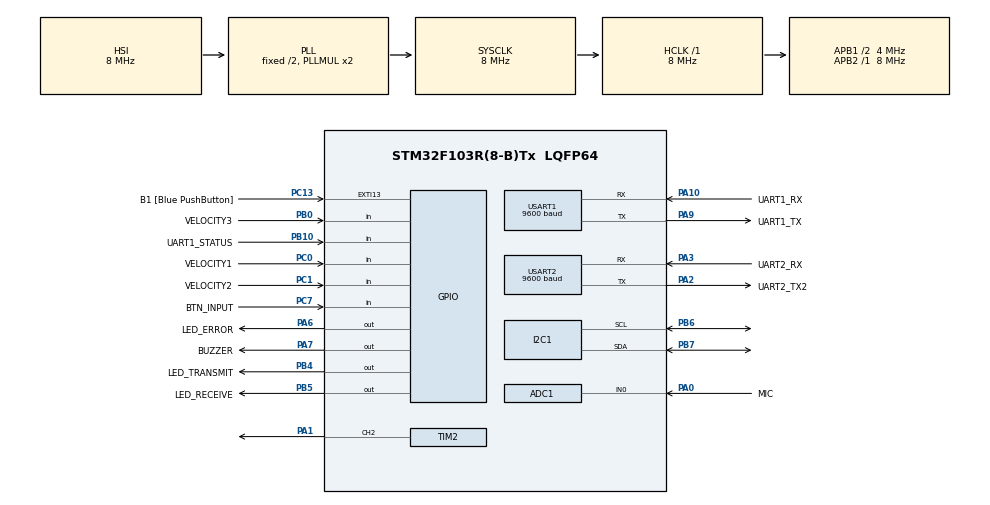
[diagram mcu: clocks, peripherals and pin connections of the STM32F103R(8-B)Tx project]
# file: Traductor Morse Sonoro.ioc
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ADC1.Channel-0\#ChannelRegularConversion=ADC_CHANNEL_0
ADC1.ContinuousConvMode=DISABLE
ADC1.ExternalTrigConv=ADC_EXTERNALTRIGCONV_T2_CC2
ADC1.NbrOfConversionFlag=1
ADC1.Rank-0\#ChannelRegularConversion=1
ADC1.SamplingTime-0\#ChannelRegularConversion=ADC_SAMPLETIME_1CYCLE_5
ADC1.master=1
Dma.ADC1.0.Direction=DMA_PERIPH_TO_MEMORY
Dma.ADC1.0.Instance=DMA1_Channel1
Dma.ADC1.0.MemDataAlignment=DMA_MDATAALIGN_HALFWORD
Dma.ADC1.0.MemInc=DMA_MINC_ENABLE
Dma.ADC1.0.Mode=DMA_NORMAL
Dma.ADC1.0.PeriphDataAlignment=DMA_PDATAALIGN_HALFWORD
Dma.ADC1.0.PeriphInc=DMA_PINC_DISABLE
Dma.ADC1.0.Priority=DMA_PRIORITY_MEDIUM
Dma.Request0=ADC1
Mcu.Family=STM32F1
Mcu.Name=STM32F103R(8-B)Tx
Mcu.Package=LQFP64
NVIC.DMA1_Channel1_IRQn=true\:0\:0\:false\:false\:true\:false\:true\:true
NVIC.EXTI15_10_IRQn=true\:0\:0\:false\:false\:true\:true\:true\:true
NVIC.PriorityGroup=NVIC_PRIORITYGROUP_4
NVIC.USART1_IRQn=true\:0\:0\:false\:false\:true\:true\:true\:true
PA0-WKUP.GPIO_Label=MIC
PA0-WKUP.Signal=ADCx_IN0
PA1.Signal=S_TIM2_CH2
PA10.GPIO_Label=UART1_RX
PA10.Mode=Asynchronous
PA10.Signal=USART1_RX
PA13.GPIO_Label=TMS
PA13.Mode=Serial_Wire
PA13.Signal=SYS_JTMS-SWDIO
PA14.GPIO_Label=TCK
PA14.Mode=Serial_Wire
PA14.Signal=SYS_JTCK-SWCLK
PA2.GPIO_Label=UART2_TX2
PA2.GPIO_Mode=GPIO_MODE_AF_PP
PA2.GPIO_PuPd=GPIO_NOPULL
PA2.GPIO_Speed=GPIO_SPEED_FREQ_LOW
PA2.Mode=Asynchronous
PA2.Signal=USART2_TX
PA3.GPIO_Label=UART2_RX
PA3.GPIO_Mode=GPIO_MODE_AF_PP
PA3.GPIO_PuPd=GPIO_NOPULL
PA3.GPIO_Speed=GPIO_SPEED_FREQ_LOW
PA3.Mode=Asynchronous
PA3.Signal=USART2_RX
PA6.GPIO_Label=LED_ERROR
PA6.Signal=GPIO_Output
PA7.GPIO_Label=BUZZER
PA7.Signal=GPIO_Output
PA9.GPIO_Label=UART1_TX
PA9.Mode=Asynchronous
PA9.Signal=USART1_TX
PB0.GPIO_Label=VELOCITY3
PB0.GPIO_PuPd=GPIO_PULLDOWN
PB0.Signal=GPIO_Input
PB10.GPIO_Label=UART1_STATUS
PB10.Signal=GPIO_Input
PB3.GPIO_Label=SWO
PB3.Signal=SYS_JTDO-TRACESWO
PB4.GPIO_Label=LED_TRANSMIT
PB4.Signal=GPIO_Output
PB5.GPIO_Label=LED_RECEIVE
PB5.Signal=GPIO_Output
PB6.Mode=I2C
PB6.Signal=I2C1_SCL
PB7.Mode=I2C
PB7.Signal=I2C1_SDA
PC0.GPIO_Label=VELOCITY1
PC0.GPIO_PuPd=GPIO_PULLDOWN
PC0.Signal=GPIO_Input
PC1.GPIO_Label=VELOCITY2
PC1.GPIO_PuPd=GPIO_PULLDOWN
PC1.Signal=GPIO_Input
PC13-TAMPER-RTC.GPIO_Label=B1 [Blue PushButton]
PC13-TAMPER-RTC.GPIO_PuPd=GPIO_NOPULL
PC13-TAMPER-RTC.Signal=GPXTI13
PC14-OSC32_IN.Mode=LSE-External-Oscillator
PC14-OSC32_IN.Signal=RCC_OSC32_IN
PC15-OSC32_OUT.Mode=LSE-External-Oscillator
PC15-OSC32_OUT.Signal=RCC_OSC32_OUT
PC7.GPIO_Label=BTN_INPUT
PC7.GPIO_PuPd=GPIO_PULLDOWN
PC7.Signal=GPIO_Input
PD0-OSC_IN.Mode=HSE-External-Clock-Source
PD0-OSC_IN.Signal=RCC_OSC_IN
PD1-OSC_OUT.Mode=HSE-External-Clock-Source
PD1-OSC_OUT.Signal=RCC_OSC_OUT
ProjectManager.HeapSize=0x200
ProjectManager.StackSize=0x400
ProjectManager.TargetToolchain=STM32CubeIDE
RCC.AHBFreq_Value=8000000
RCC.APB1CLKDivider=RCC_HCLK_DIV2
RCC.APB1Freq_Value=4000000
RCC.APB1TimFreq_Value=8000000
RCC.APB2Freq_Value=8000000
RCC.APB2TimFreq_Value=8000000
RCC.HCLKFreq_Value=8000000
RCC.RTCClockSelection=RCC_RTCCLKSOURCE_LSE
RCC.SYSCLKFreq_VALUE=8000000
RCC.SYSCLKSource=RCC_SYSCLKSOURCE_PLLCLK
RCC.USBFreq_Value=8000000
SH.ADCx_IN0.0=ADC1_IN0,IN0
SH.S_TIM2_CH2.0=TIM2_CH2,Output Compare2 CH2
TIM2.AutoReloadPreload=TIM_AUTORELOAD_PRELOAD_ENABLE
TIM2.Channel-Output\ Compare2\ CH2=TIM_CHANNEL_2
TIM2.OCMode_2=TIM_OCMODE_TOGGLE
TIM2.Period=99
TIM2.Prescaler=7
TIM2.Pulse-Output\ Compare2\ CH2=99
TIM2.TIM_MasterOutputTrigger=TIM_TRGO_UPDATE
USART1.BaudRate=9600
USART1.VirtualMode=VM_ASYNC
USART1.WordLength=WORDLENGTH_8B
USART2.BaudRate=9600
USART2.VirtualMode=VM_ASYNC
VP_TIM2_VS_ClockSourceINT.Mode=Internal
board=NUCLEO-F103RB

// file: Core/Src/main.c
/* USER CODE BEGIN Header */
/**
  ******************************************************************************
  * @file           : main.c
  * @brief          : Main program body
  ******************************************************************************
  * @attention
  *
  * Copyright (c) 2025 STMicroelectronics.
  * All rights reserved.
  *
  * This software is licensed under terms that can be found in the LICENSE file
  * in the root directory of this software component.
  * If no LICENSE file comes with this software, it is provided AS-IS.
  *
  ******************************************************************************
  */
/* USER CODE END Header */
#include "main.h"
#include "adc.h"
#include "dma.h"
#include "i2c.h"
#include "tim.h"
#include "usart.h"
#include "gpio.h"

/* USER CODE BEGIN Includes */
#include "app.h"
#include "logger.h"
/* USER CODE END Includes */

void SystemClock_Config(void);

/* USER CODE BEGIN 0 */
#if (1 == LOGGER_CONFIG_USE_SEMIHOSTING)

extern void initialise_monitor_handles(void);

#endif
/* USER CODE END 0 */

int main(void)
{

  /* USER CODE BEGIN 1 */
  #if (1 == LOGGER_CONFIG_USE_SEMIHOSTING)

  	  initialise_monitor_handles();

  #endif
  /* USER CODE END 1 */

  /* MCU Configuration--------------------------------------------------------*/

  /* Reset of all peripherals, Initializes the Flash interface and the Systick. */
  HAL_Init();

  /* Configure the system clock */
  SystemClock_Config();

  /* Initialize all configured peripherals */
  MX_GPIO_Init();
  MX_DMA_Init();
  MX_USART2_UART_Init();
  MX_USART1_UART_Init();
  MX_ADC1_Init();
  MX_TIM2_Init();
  MX_I2C1_Init();
  /* USER CODE BEGIN 2 */
  app_init();
  /* USER CODE END 2 */

  /* Infinite loop */
  /* USER CODE BEGIN WHILE */
  while (1)
  {
	app_update();
    /* USER CODE END WHILE */

  }
}

void SystemClock_Config(void)
{
  RCC_OscInitTypeDef RCC_OscInitStruct = {0};
  RCC_ClkInitTypeDef RCC_ClkInitStruct = {0};
  RCC_PeriphCLKInitTypeDef PeriphClkInit = {0};

  /** Initializes the RCC Oscillators according to the specified parameters
  * in the RCC_OscInitTypeDef structure.
  */
  RCC_OscInitStruct.OscillatorType = RCC_OSCILLATORTYPE_HSI;
  RCC_OscInitStruct.HSIState = RCC_HSI_ON;
  RCC_OscInitStruct.HSICalibrationValue = RCC_HSICALIBRATION_DEFAULT;
  RCC_OscInitStruct.PLL.PLLState = RCC_PLL_ON;
  RCC_OscInitStruct.PLL.PLLSource = RCC_PLLSOURCE_HSI_DIV2;
  RCC_OscInitStruct.PLL.PLLMUL = RCC_PLL_MUL2;
  if (HAL_RCC_OscConfig(&RCC_OscInitStruct) != HAL_OK)
  {
    Error_Handler();
  }

  /** Initializes the CPU, AHB and APB buses clocks
  */
  RCC_ClkInitStruct.ClockType = RCC_CLOCKTYPE_HCLK|RCC_CLOCKTYPE_SYSCLK
                              |RCC_CLOCKTYPE_PCLK1|RCC_CLOCKTYPE_PCLK2;
  RCC_ClkInitStruct.SYSCLKSource = RCC_SYSCLKSOURCE_PLLCLK;
  RCC_ClkInitStruct.AHBCLKDivider = RCC_SYSCLK_DIV1;
  RCC_ClkInitStruct.APB1CLKDivider = RCC_HCLK_DIV2;
  RCC_ClkInitStruct.APB2CLKDivider = RCC_HCLK_DIV1;

  if (HAL_RCC_ClockConfig(&RCC_ClkInitStruct, FLASH_LATENCY_0) != HAL_OK)
  {
    Error_Handler();
  }
  PeriphClkInit.PeriphClockSelection = RCC_PERIPHCLK_ADC;
  PeriphClkInit.AdcClockSelection = RCC_ADCPCLK2_DIV2;
  if (HAL_RCCEx_PeriphCLKConfig(&PeriphClkInit) != HAL_OK)
  {
    Error_Handler();
  }
}

void Error_Handler(void)
{
  __disable_irq();
  while (1)
  {
  }
}
